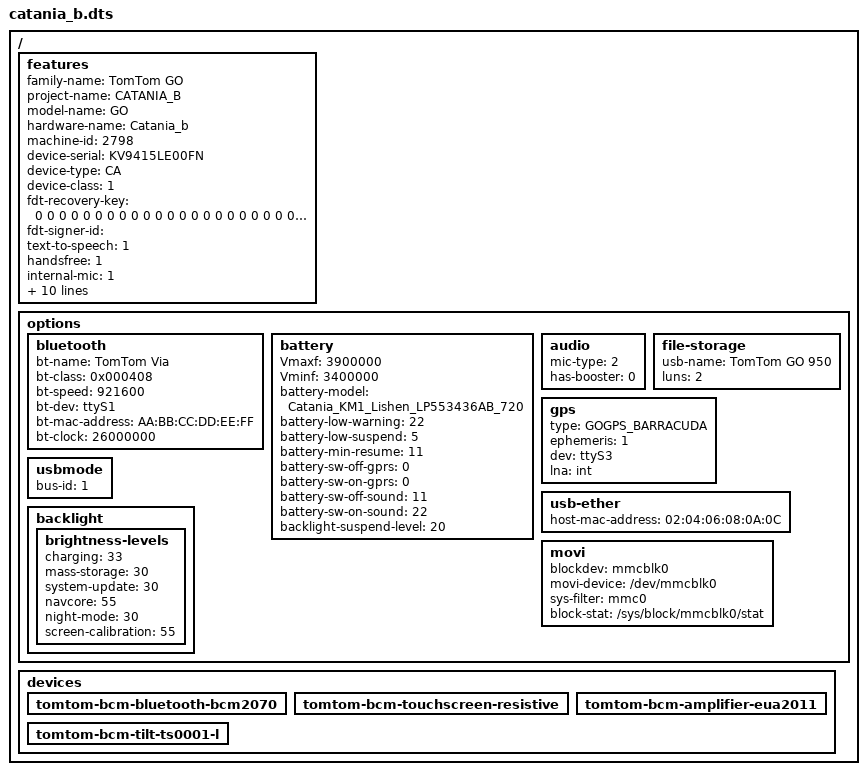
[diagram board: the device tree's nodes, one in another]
/dts-v1/;

/ {
	features {
		family-name			= "TomTom GO";
		project-name			= "CATANIA_B";
		model-name			= "GO";
		hardware-name			= "Catania_b";
		machine-id			= <2798>;
		device-serial			= "KV9415LE00FN";
		device-type			= "CA";
		device-class			= <1>;
		fdt-recovery-key		= <
			0 0 0 0 0 0 0 0 0 0 0 0 0 0 0 0 0 0 0 0 0 0 0 0 0 0 0 0 0 0 0 0
			0 0 0 0 0 0 0 0 0 0 0 0 0 0 0 0 0 0 0 0 0 0 0 0 0 0 0 0 0 0 0 0
			0 0 0 0 0 0 0 0 0 0 0 0 0 0 0 0 0 0 0 0 0 0 0 0 0 0 0 0 0 0 0 0
			0 0 0 0 0 0 0 0 0 0 0 0 0 0 0 0 0 0 0 0 0 0 0 0 0 0 0 0 0 0 0 0
		>;
		fdt-signer-id			= "";
		text-to-speech			= <1>;
		handsfree			= <1>;
		internal-mic			= <1>;
		voice-recording			= <1>;
		connect-ext-mic			= <0>;
		sdcard				= <0>;
		uart-id				= <2>;
		has-gprs			= <0>;
		has-tilt-sensor			= <1>;
		has-bluetooth			= <1>;
		bluetooth			= "BCM2070";
		amplifier			= "EUA2011";
		tft 				= "LMS430";
	};

	options {
		bluetooth {
			bt-name 			= "TomTom Via";
			bt-class 			= <0x000408>;
			bt-speed 			= <921600>;
			bt-dev 				= "ttyS1";
			bt-mac-address 			= "AA:BB:CC:DD:EE:FF";
			bt-clock 			= <26000000>;

		};

		battery {
			Vmaxf				= <3900000>;
			Vminf				= <3400000>;
			/* The battery model is composed as: packvendor_cellvendor_batterytype_batterycapacity */
			battery-model			= "Catania_KM1_Lishen_LP553436AB_720";
			battery-low-warning		= <22>;
			battery-low-suspend		= <5>;
			battery-min-resume		= <11>;
			battery-sw-off-gprs		= <0>;
			battery-sw-on-gprs		= <0>;
			battery-sw-off-sound		= <11>;
			battery-sw-on-sound		= <22>;
			backlight-suspend-level		= <20>;
		};

		audio {
			mic-type			= <2>;	/* 1 = rubber mic, 2 = SMT mic */
			has-booster			= <0>;
		};

		file-storage {
			usb-name			= "TomTom GO 950";
			luns				= <2>;
		};

		gps {
			type 				= "GOGPS_BARRACUDA";
			ephemeris			= <1>;			
			dev				= "ttyS3";
			lna				= "int";
		};

		usb-ether 
		{
			host-mac-address		= "02:04:06:08:0A:0C";
		};

		usbmode 
		{
			/* usbmode related , the id of the usbmode driver needs change */
			bus-id				= <1>; 
		};

		backlight 
		{
			brightness-levels 
			{
				charging		= <33>;
				mass-storage		= <30>;
				system-update		= <30>;
				navcore			= <55>;
				night-mode		= <30>;
				screen-calibration	= <55>;
			};
		};

		movi { 
			blockdev 	= "mmcblk0";
			movi-device 	= "/dev/mmcblk0";
			sys-filter 	= "mmc0";
			block-stat 	= "/sys/block/mmcblk0/stat";
		};

	};

	/* list of tomtom methods that need implementing: adding items as devices
	will cause tt_setup to register the services */
	devices 
	{
		tomtom-bcm-bluetooth-bcm2070 {};
		tomtom-bcm-touchscreen-resistive {};
		tomtom-bcm-amplifier-eua2011 {};
		tomtom-bcm-tilt-ts0001-l {};
	};
};
